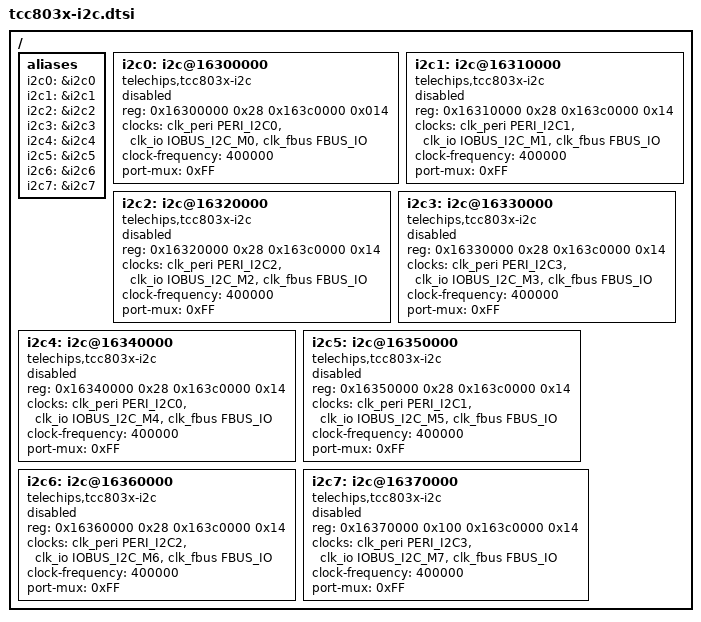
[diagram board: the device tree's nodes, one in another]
// SPDX-License-Identifier: (GPL-2.0-or-later OR MIT)
/*
 * Copyright (C) 2023 Telechips Inc.
 */

#include <dt-bindings/clock/telechips,tcc803x-clks.h>

/ {
	aliases: aliases {
		i2c0 = &i2c0;
		i2c1 = &i2c1;
		i2c2 = &i2c2;
		i2c3 = &i2c3;
		i2c4 = &i2c4;
		i2c5 = &i2c5;
		i2c6 = &i2c6;
		i2c7 = &i2c7;
	};

	i2c0: i2c@16300000 {
		compatible = "telechips,tcc803x-i2c";
		reg = <0x16300000 0x28 0x163c0000 0x014>;
		#address-cells = <1>;
		#size-cells = <0>;
		clocks = <&clk_peri PERI_I2C0 &clk_io IOBUS_I2C_M0
			  &clk_fbus FBUS_IO>;
		clock-frequency = <400000>;
		port-mux = <0xFF>;	/* default value */
		status = "disabled";
	};

	i2c1: i2c@16310000 {
		compatible = "telechips,tcc803x-i2c";
		reg = <0x16310000 0x28 0x163c0000 0x14>;
		#address-cells = <1>;
		#size-cells = <0>;
		clocks = <&clk_peri PERI_I2C1 &clk_io IOBUS_I2C_M1
			  &clk_fbus FBUS_IO>;
		clock-frequency = <400000>;
		port-mux = <0xFF>;	/* default value */
		status = "disabled";
	};

	i2c2: i2c@16320000 {
		compatible = "telechips,tcc803x-i2c";
		reg = <0x16320000 0x28 0x163c0000 0x14>;
		#address-cells = <1>;
		#size-cells = <0>;
		clocks = <&clk_peri PERI_I2C2 &clk_io IOBUS_I2C_M2
			  &clk_fbus FBUS_IO>;
		clock-frequency = <400000>;
		port-mux = <0xFF>;	/* default value */
		status = "disabled";
	};

	i2c3: i2c@16330000 {
		compatible = "telechips,tcc803x-i2c";
		reg = <0x16330000 0x28 0x163c0000 0x14>;
		#address-cells = <1>;
		#size-cells = <0>;
		clocks = <&clk_peri PERI_I2C3 &clk_io IOBUS_I2C_M3
			  &clk_fbus FBUS_IO>;
		clock-frequency = <400000>;
		port-mux = <0xFF>;	/* default value */
		status = "disabled";
	};

	i2c4: i2c@16340000 {
		compatible = "telechips,tcc803x-i2c";
		reg = <0x16340000 0x28 0x163c0000 0x14>;
		#address-cells = <1>;
		#size-cells = <0>;
		clocks = <&clk_peri PERI_I2C0 &clk_io IOBUS_I2C_M4
			  &clk_fbus FBUS_IO>;
		clock-frequency = <400000>;
		port-mux = <0xFF>;	/* default value */
		status = "disabled";
	};

	i2c5: i2c@16350000 {
		compatible = "telechips,tcc803x-i2c";
		reg = <0x16350000 0x28 0x163c0000 0x14>;
		#address-cells = <1>;
		#size-cells = <0>;
		clocks = <&clk_peri PERI_I2C1 &clk_io IOBUS_I2C_M5
			  &clk_fbus FBUS_IO>;
		clock-frequency = <400000>;
		port-mux = <0xFF>;	/* default value */
		status = "disabled";
	};

	i2c6: i2c@16360000 {
		compatible = "telechips,tcc803x-i2c";
		reg = <0x16360000 0x28 0x163c0000 0x14>;
		#address-cells = <1>;
		#size-cells = <0>;
		clocks = <&clk_peri PERI_I2C2 &clk_io IOBUS_I2C_M6
			  &clk_fbus FBUS_IO>;
		clock-frequency = <400000>;
		port-mux = <0xFF>;	/* default value */
		status = "disabled";
	};

	i2c7: i2c@16370000 {
		compatible = "telechips,tcc803x-i2c";
		reg = <0x16370000 0x100 0x163c0000 0x14>;
		#address-cells = <1>;
		#size-cells = <0>;
		clocks = <&clk_peri PERI_I2C3 &clk_io IOBUS_I2C_M7
			  &clk_fbus FBUS_IO>;
		clock-frequency = <400000>;
		port-mux = <0xFF>;	/* default value */
		status = "disabled";
	};
};
